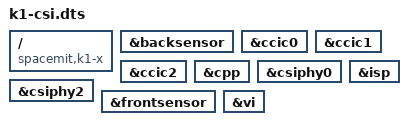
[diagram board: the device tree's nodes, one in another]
/dts-v1/;
/plugin/;

/ {
	compatible = "spacemit,k1-x";

	fragment@0 {
		target = <&backsensor>;
		__overlay__ {
			status = "okay";
		};
	};

	fragment@1 {
		target = <&ccic0>;
		__overlay__ {
			status = "okay";
		};
	};

	fragment@2 {
		target = <&ccic1>;
		__overlay__ {
			status = "okay";
		};
	};

	fragment@3 {
		target = <&ccic2>;
		__overlay__ {
			status = "okay";
		};
	};

	fragment@4 {
		target = <&cpp>;
		__overlay__ {
			status = "okay";
		};
	};

	fragment@5 {
		target = <&csiphy0>;
		__overlay__ {
			status = "okay";
		};
	};

	fragment@6 {
		target = <&csiphy2>;
		__overlay__ {
			status = "okay";
		};
	};

	fragment@7 {
		target = <&frontsensor>;
		__overlay__ {
			status = "okay";
		};
	};

	fragment@8 {
		target = <&isp>;
		__overlay__ {
			status = "okay";
		};
	};

	fragment@9 {
		target = <&vi>;
		__overlay__ {
			status = "okay";
		};
	};
};
